# RESTORE_CM2 register map
Vendor: Texas Instruments
Peripheral module from a debugger description file (folder omap4460).
Registers are 32-bit, access per field, reset 0x0 unless marked. A register's access mark holds for its fields unless they carry their own. Offsets are as the file gives them; lines under a group give offsets from that group; [hi:lo] are bit positions; {n}, {i} and the like mark numbered series; 'fields as' and 'values as' point back to an identical list; <NAME> marks a mode.

## RESTORE_CM2
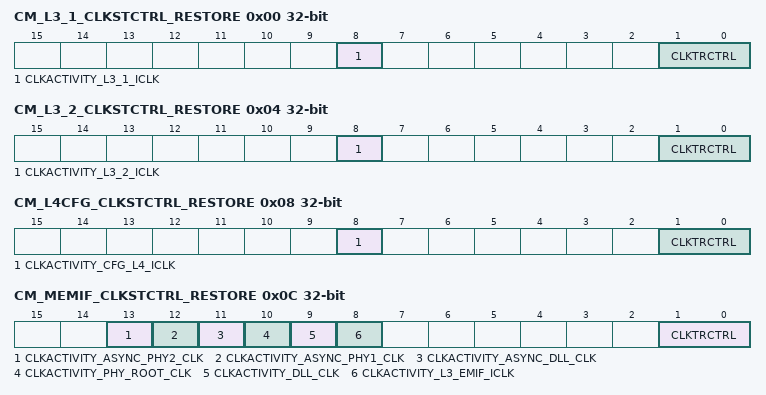
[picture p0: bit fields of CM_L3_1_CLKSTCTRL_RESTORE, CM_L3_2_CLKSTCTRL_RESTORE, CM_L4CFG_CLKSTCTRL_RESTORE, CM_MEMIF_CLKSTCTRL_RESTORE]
0x00 CM_L3_1_CLKSTCTRL_RESTORE — Second address map for register. Used only by automatic restore upon wakeup from device OFF mode.
  [8] CLKACTIVITY_L3_1_ICLK ro — This field indicates the state of the L3_1_GICLK clock in the domain. [warm reset insensitive]
    0=CLKACTIVITY_L3_1_ICLK_0_r (Corresponding clock is definitely gated); 1=CLKACTIVITY_L3_1_ICLK_1_r (Corresponding clock is running or gating/ungating transition is ongoing)
  [1:0] CLKTRCTRL rw — Controls the clock state transition of the L3_1 clock domain.
    0=NO_SLEEP: Sleep transition cannot be initiated. Wakeup transition may however occur.; 1=CLKTRCTRL_1_r (Reserved); 2=CLKTRCTRL_2_r (Reserved); 3=HW_AUTO: Automatic transition is enabled. Sleep and wakeup transition are based upon hardware conditions.
0x04 CM_L3_2_CLKSTCTRL_RESTORE — Second address map for register. Used only by automatic restore upon wakeup from device OFF mode.
  [8] CLKACTIVITY_L3_2_ICLK ro — This field indicates the state of the L3_2_GICLK clock in the domain. [warm reset insensitive]
    0=CLKACTIVITY_L3_2_ICLK_0_r (Corresponding clock is definitely gated); 1=CLKACTIVITY_L3_2_ICLK_1_r (Corresponding clock is running or gating/ungating transition is ongoing)
  [1:0] CLKTRCTRL rw — Controls the clock state transition of the L3_2 clock domain.
    values as CM_L3_1_CLKSTCTRL_RESTORE.CLKTRCTRL
0x08 CM_L4CFG_CLKSTCTRL_RESTORE — Second address map for register. Used only by automatic restore upon wakeup from device OFF mode.
  [8] CLKACTIVITY_CFG_L4_ICLK ro — This field indicates the state of the L4_CFG_GICLK clock in the domain. [warm reset insensitive]
    0=CLKACTIVITY_CFG_L4_ICLK_0_r (Corresponding clock is definitely gated); 1=CLKACTIVITY_CFG_L4_ICLK_1_r (Corresponding clock is running or gating/ungating transition is ongoing)
  [1:0] CLKTRCTRL rw — Controls the clock state transition of the L4CFG clock domain.
    values as CM_L3_1_CLKSTCTRL_RESTORE.CLKTRCTRL
0x0C CM_MEMIF_CLKSTCTRL_RESTORE — Second address map for register. Used only by automatic restore upon wakeup from device OFF mode.
  [13] CLKACTIVITY_ASYNC_PHY2_CLK ro — This field indicates the state of the ASYNC_PHY2_CLK clock in the domain. [warm reset insensitive]
    0=CLKACTIVITY_ASYNC_PHY2_CLK_0_r (Corresponding clock is definitely gated); 1=CLKACTIVITY_ASYNC_PHY2_CLK_1_r (Corresponding clock is running or gating/ungating transition is ongoing)
  [12] CLKACTIVITY_ASYNC_PHY1_CLK ro — This field indicates the state of the ASYNC_PHY1_CLK clock in the domain. [warm reset insensitive]
    0=CLKACTIVITY_ASYNC_PHY1_CLK_0_r (Corresponding clock is definitely gated); 1=CLKACTIVITY_ASYNC_PHY1_CLK_1_r (Corresponding clock is running or gating/ungating transition is ongoing)
  [11] CLKACTIVITY_ASYNC_DLL_CLK ro — This field indicates the state of the ASYNC_DLL_CLK clock in the domain. [warm reset insensitive]
    0=CLKACTIVITY_ASYNC_DLL_CLK_0_r (Corresponding clock is definitely gated); 1=CLKACTIVITY_ASYNC_DLL_CLK_1_r (Corresponding clock is running or gating/ungating transition is ongoing)
  [10] CLKACTIVITY_PHY_ROOT_CLK ro — This field indicates the state of the PHY_ROOT_CLK clock in the domain. [warm reset insensitive]
    0=CLKACTIVITY_PHY_ROOT_CLK_0_r (Corresponding clock is definitely gated); 1=CLKACTIVITY_PHY_ROOT_CLK_1_r (Corresponding clock is running or gating/ungating transition is ongoing)
  [9] CLKACTIVITY_DLL_CLK ro — This field indicates the state of the DLL_CLK clock in the domain. [warm reset insensitive]
    0=CLKACTIVITY_DLL_CLK_0_r (Corresponding clock is definitely gated); 1=CLKACTIVITY_DLL_CLK_1_r (Corresponding clock is running or gating/ungating transition is ongoing)
  [8] CLKACTIVITY_L3_EMIF_ICLK ro — This field indicates the state of the L3_EMIF_GICLK clock in the domain. [warm reset insensitive]
    0=CLKACTIVITY_L3_EMIF_ICLK_0_r (Corresponding clock is definitely gated); 1=CLKACTIVITY_L3_EMIF_ICLK_1_r (Corresponding clock is running or gating/ungating transition is ongoing)
  [1:0] CLKTRCTRL rw — Controls the clock state transition of the MEMIF clock domain.
    0=NO_SLEEP: Sleep transition cannot be initiated. Wakeup transition may however occur.; 1=CLKTRCTRL_1_r (Reserved); 2=SW_WKUP: Start a software forced wake-up transition on the domain; 3=HW_AUTO: Automatic transition is enabled. Sleep and wakeup transition are based upon hardware conditions.
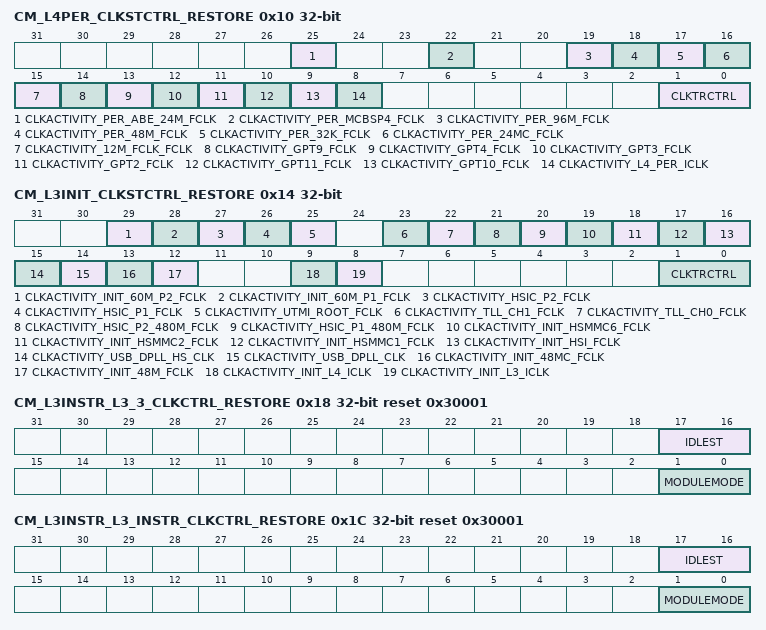
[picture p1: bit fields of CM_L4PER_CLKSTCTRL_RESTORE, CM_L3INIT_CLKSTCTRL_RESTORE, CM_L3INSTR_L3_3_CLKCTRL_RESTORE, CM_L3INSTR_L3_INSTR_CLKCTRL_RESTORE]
0x10 CM_L4PER_CLKSTCTRL_RESTORE — Second address map for register. Used only by automatic restore upon wakeup from device OFF mode.
  [25] CLKACTIVITY_PER_ABE_24M_FCLK ro — This field indicates the state of the PER_ABE_24M_FCLK clock in the domain. [warm reset insensitive]
    0=CLKACTIVITY_PER_ABE_24M_FCLK_0_r (Corresponding clock is definitely gated); 1=CLKACTIVITY_PER_ABE_24M_FCLK_1_r (Corresponding clock is running or gating/ungating transition is ongoing)
  [22] CLKACTIVITY_PER_MCBSP4_FCLK ro — This field indicates the state of the PER_MCBSP4_FCLK clock in the domain. [warm reset insensitive]
    0=CLKACTIVITY_PER_MCBSP4_FCLK_0_r (Corresponding clock is definitely gated); 1=CLKACTIVITY_PER_MCBSP4_FCLK_1_r (Corresponding clock is running or gating/ungating transition is ongoing)
  [19] CLKACTIVITY_PER_96M_FCLK ro — This field indicates the state of the PER_96M_FCLK clock in the domain. [warm reset insensitive]
    0=CLKACTIVITY_PER_96M_FCLK_0_r (Corresponding clock is definitely gated); 1=CLKACTIVITY_PER_96M_FCLK_1_r (Corresponding clock is running or gating/ungating transition is ongoing)
  [18] CLKACTIVITY_PER_48M_FCLK ro — This field indicates the state of the PER_48M_FCLK clock in the domain. [warm reset insensitive]
    0=CLKACTIVITY_PER_48M_FCLK_0_r (Corresponding clock is definitely gated); 1=CLKACTIVITY_PER_48M_FCLK_1_r (Corresponding clock is running or gating/ungating transition is ongoing)
  [17] CLKACTIVITY_PER_32K_FCLK ro — This field indicates the state of the PER_32K_FCLK clock in the domain. [warm reset insensitive]
    0=CLKACTIVITY_PER_32K_FCLK_0_r (Corresponding clock is definitely gated); 1=CLKACTIVITY_PER_32K_FCLK_1_r (Corresponding clock is running or gating/ungating transition is ongoing)
  [16] CLKACTIVITY_PER_24MC_FCLK ro — This field indicates the state of the PER_24MC_FCLK clock in the domain. [warm reset insensitive]
    0=CLKACTIVITY_PER_24MC_FCLK_0_r (Corresponding clock is definitely gated); 1=CLKACTIVITY_PER_24MC_FCLK_1_r (Corresponding clock is running or gating/ungating transition is ongoing)
  [15] CLKACTIVITY_12M_FCLK_FCLK ro — This field indicates the state of the FUNC_12M_FCLK clock in the domain. [warm reset insensitive]
    0=CLKACTIVITY_12M_FCLK_FCLK_0_r (Corresponding clock is definitely gated); 1=CLKACTIVITY_12M_FCLK_FCLK_1_r (Corresponding clock is running or gating/ungating transition is ongoing)
  [14] CLKACTIVITY_GPT9_FCLK ro — This field indicates the state of the DMT9_FCLK clock in the domain. [warm reset insensitive]
    0=CLKACTIVITY_GPT9_FCLK_0_r (Corresponding clock is definitely gated); 1=CLKACTIVITY_GPT9_FCLK_1_r (Corresponding clock is running or gating/ungating transition is ongoing)
  [13] CLKACTIVITY_GPT4_FCLK ro — This field indicates the state of the DMT4_FCLK clock in the domain. [warm reset insensitive]
    0=CLKACTIVITY_GPT4_FCLK_0_r (Corresponding clock is definitely gated); 1=CLKACTIVITY_GPT4_FCLK_1_r (Corresponding clock is running or gating/ungating transition is ongoing)
  [12] CLKACTIVITY_GPT3_FCLK ro — This field indicates the state of the DMT3_FCLK clock in the domain. [warm reset insensitive]
    0=CLKACTIVITY_GPT3_FCLK_0_r (Corresponding clock is definitely gated); 1=CLKACTIVITY_GPT3_FCLK_1_r (Corresponding clock is running or gating/ungating transition is ongoing)
  [11] CLKACTIVITY_GPT2_FCLK ro — This field indicates the state of the DMT2_FCLK clock in the domain. [warm reset insensitive]
    0=CLKACTIVITY_GPT2_FCLK_0_r (Corresponding clock is definitely gated); 1=CLKACTIVITY_GPT2_FCLK_1_r (Corresponding clock is running or gating/ungating transition is ongoing)
  [10] CLKACTIVITY_GPT11_FCLK ro — This field indicates the state of the DMT11_FCLK clock in the domain. [warm reset insensitive]
    0=CLKACTIVITY_GPT11_FCLK_0_r (Corresponding clock is definitely gated); 1=CLKACTIVITY_GPT11_FCLK_1_r (Corresponding clock is running or gating/ungating transition is ongoing)
  [9] CLKACTIVITY_GPT10_FCLK ro — This field indicates the state of the DMT10_FCLK clock in the domain. [warm reset insensitive]
    0=CLKACTIVITY_GPT10_FCLK_0_r (Corresponding clock is definitely gated); 1=CLKACTIVITY_GPT10_FCLK_1_r (Corresponding clock is running or gating/ungating transition is ongoing)
  [8] CLKACTIVITY_L4_PER_ICLK ro — This field indicates the state of the L4_PER_GICLK clock in the domain. [warm reset insensitive]
    0=CLKACTIVITY_L4_PER_ICLK_0_r (Corresponding clock is definitely gated); 1=CLKACTIVITY_L4_PER_ICLK_1_r (Corresponding clock is running or gating/ungating transition is ongoing)
  [1:0] CLKTRCTRL rw — Controls the clock state transition of the L4PER clock domain.
    0=NO_SLEEP: Sleep transition cannot be initiated. Wakeup transition may however occur.; 1=SW_SLEEP: Start a software forced sleep transition on the domain; 2=SW_WKUP: Start a software forced wake-up transition on the domain; 3=HW_AUTO: Automatic transition is enabled. Sleep and wakeup transition are based upon hardware conditions.
0x14 CM_L3INIT_CLKSTCTRL_RESTORE — Second address map for register. Used only by automatic restore upon wakeup from device OFF mode.
  [29] CLKACTIVITY_INIT_60M_P2_FCLK ro — This field indicates the state of the INIT_60M_P2_FCLK clock in the domain. [warm reset insensitive]
    0=CLKACTIVITY_INIT_60M_P2_FCLK_0_r (Corresponding clock is definitely gated); 1=CLKACTIVITY_INIT_60M_P2_FCLK_1_r (Corresponding clock is running or gating/ungating transition is ongoing)
  [28] CLKACTIVITY_INIT_60M_P1_FCLK ro — This field indicates the state of the INIT_60M_P1_FCLK clock in the domain. [warm reset insensitive]
    0=CLKACTIVITY_INIT_60M_P1_FCLK_0_r (Corresponding clock is definitely gated); 1=CLKACTIVITY_INIT_60M_P1_FCLK_1_r (Corresponding clock is running or gating/ungating transition is ongoing)
  [27] CLKACTIVITY_HSIC_P2_FCLK ro — This field indicates the state of the HSIC_P2_FCLK clock in the domain. [warm reset insensitive]
    0=CLKACTIVITY_HSIC_P2_FCLK_0_r (Corresponding clock is definitely gated); 1=CLKACTIVITY_HSIC_P2_FCLK_1_r (Corresponding clock is running or gating/ungating transition is ongoing)
  [26] CLKACTIVITY_HSIC_P1_FCLK ro — This field indicates the state of the HSIC_P1_FCLK clock in the domain. [warm reset insensitive]
    0=CLKACTIVITY_HSIC_P1_FCLK_0_r (Corresponding clock is definitely gated); 1=CLKACTIVITY_HSIC_P1_FCLK_1_r (Corresponding clock is running or gating/ungating transition is ongoing)
  [25] CLKACTIVITY_UTMI_ROOT_FCLK ro — This field indicates the state of the UTMI_ROOT_FCLK clock in the domain. [warm reset insensitive]
    0=CLKACTIVITY_UTMI_ROOT_FCLK_0_r (Corresponding clock is definitely gated); 1=CLKACTIVITY_UTMI_ROOT_FCLK_1_r (Corresponding clock is running or gating/ungating transition is ongoing)
  [23] CLKACTIVITY_TLL_CH1_FCLK ro — This field indicates the state of the TLL_CH1_FCLK clock in the domain. [warm reset insensitive]
    0=CLKACTIVITY_TLL_CH1_FCLK_0_r (Corresponding clock is definitely gated); 1=CLKACTIVITY_TLL_CH1_FCLK_1_r (Corresponding clock is running or gating/ungating transition is ongoing)
  [22] CLKACTIVITY_TLL_CH0_FCLK ro — This field indicates the state of the TLL_CH0_FCLK clock in the domain. [warm reset insensitive]
    0=CLKACTIVITY_TLL_CH0_FCLK_0_r (Corresponding clock is definitely gated); 1=CLKACTIVITY_TLL_CH0_FCLK_1_r (Corresponding clock is running or gating/ungating transition is ongoing)
  [21] CLKACTIVITY_HSIC_P2_480M_FCLK ro — This field indicates the state of the HSIC_P2_480M_FCLK clock in the domain. [warm reset insensitive]
    0=CLKACTIVITY_HSIC_P2_480M_FCLK_0_r (Corresponding clock is definitely gated); 1=CLKACTIVITY_HSIC_P2_480M_FCLK_1_r (Corresponding clock is running or gating/ungating transition is ongoing)
  [20] CLKACTIVITY_HSIC_P1_480M_FCLK ro — This field indicates the state of the HSIC_P1_480M_FCLK clock in the domain. [warm reset insensitive]
    0=CLKACTIVITY_HSIC_P1_480M_FCLK_0_r (Corresponding clock is definitely gated); 1=CLKACTIVITY_HSIC_P1_480M_FCLK_1_r (Corresponding clock is running or gating/ungating transition is ongoing)
  [19] CLKACTIVITY_INIT_HSMMC6_FCLK ro — This field indicates the state of the INIT_HSMMC6_FCLK clock in the domain. [warm reset insensitive]
    0=CLKACTIVITY_INIT_HSMMC6_FCLK_0_r (Corresponding clock is definitely gated); 1=CLKACTIVITY_INIT_HSMMC6_FCLK_1_r (Corresponding clock is running or gating/ungating transition is ongoing)
  [18] CLKACTIVITY_INIT_HSMMC2_FCLK ro — This field indicates the state of the INIT_HSMMC2_FCLK clock in the domain. [warm reset insensitive]
    0=CLKACTIVITY_INIT_HSMMC2_FCLK_0_r (Corresponding clock is definitely gated); 1=CLKACTIVITY_INIT_HSMMC2_FCLK_1_r (Corresponding clock is running or gating/ungating transition is ongoing)
  [17] CLKACTIVITY_INIT_HSMMC1_FCLK ro — This field indicates the state of the INIT_HSMMC1_FCLK clock in the domain. [warm reset insensitive]
    0=CLKACTIVITY_INIT_HSMMC1_FCLK_0_r (Corresponding clock is definitely gated); 1=CLKACTIVITY_INIT_HSMMC1_FCLK_1_r (Corresponding clock is running or gating/ungating transition is ongoing)
  [16] CLKACTIVITY_INIT_HSI_FCLK ro — This field indicates the state of the INIT_HSI_FCLK clock in the domain. [warm reset insensitive]
    0=CLKACTIVITY_INIT_HSI_FCLK_0_r (Corresponding clock is definitely gated); 1=CLKACTIVITY_INIT_HSI_FCLK_1_r (Corresponding clock is running or gating/ungating transition is ongoing)
  [15] CLKACTIVITY_USB_DPLL_HS_CLK ro — This field indicates the state of the USB_DPLL_HS_CLK clock in the domain. [warm reset insensitive]
    0=CLKACTIVITY_USB_DPLL_HS_CLK_0_r (Corresponding clock is definitely gated); 1=CLKACTIVITY_USB_DPLL_HS_CLK_1_r (Corresponding clock is running or gating/ungating transition is ongoing)
  [14] CLKACTIVITY_USB_DPLL_CLK ro — This field indicates the state of the USB_DPLL_CLK clock in the domain. [warm reset insensitive]
    0=CLKACTIVITY_USB_DPLL_CLK_0_r (Corresponding clock is definitely gated); 1=CLKACTIVITY_USB_DPLL_CLK_1_r (Corresponding clock is running or gating/ungating transition is ongoing)
  [13] CLKACTIVITY_INIT_48MC_FCLK ro — This field indicates the state of the INIT_48MC_FCLK clock in the domain. [warm reset insensitive]
    0=CLKACTIVITY_INIT_48MC_FCLK_0_r (Corresponding clock is definitely gated); 1=CLKACTIVITY_INIT_48MC_FCLK_1_r (Corresponding clock is running or gating/ungating transition is ongoing)
  [12] CLKACTIVITY_INIT_48M_FCLK ro — This field indicates the state of the INIT_48M_FCLK clock in the domain. [warm reset insensitive]
    0=CLKACTIVITY_INIT_48M_FCLK_0_r (Corresponding clock is definitely gated); 1=CLKACTIVITY_INIT_48M_FCLK_1_r (Corresponding clock is running or gating/ungating transition is ongoing)
  [9] CLKACTIVITY_INIT_L4_ICLK ro — This field indicates the state of the L4_INIT_GICLK clock in the domain. [warm reset insensitive]
    0=CLKACTIVITY_INIT_L4_ICLK_0_r (Corresponding clock is definitely gated); 1=CLKACTIVITY_INIT_L4_ICLK_1_r (Corresponding clock is running or gating/ungating transition is ongoing)
  [8] CLKACTIVITY_INIT_L3_ICLK ro — This field indicates the state of the L3_INIT_GICLK clock in the domain. [warm reset insensitive]
    0=CLKACTIVITY_INIT_L3_ICLK_0_r (Corresponding clock is definitely gated); 1=CLKACTIVITY_INIT_L3_ICLK_1_r (Corresponding clock is running or gating/ungating transition is ongoing)
  [1:0] CLKTRCTRL rw — Controls the clock state transition of the L3INIT clock domain.
    values as CM_L4PER_CLKSTCTRL_RESTORE.CLKTRCTRL
0x18 CM_L3INSTR_L3_3_CLKCTRL_RESTORE reset 0x30001 — Second address map for register. Used only by automatic restore upon wakeup from device OFF mode.
  [17:16] IDLEST ro — Module idle status. [warm reset insensitive]
    0=IDLEST_0_r (Module is fully functional, including INTRCONN); 1=IDLEST_1_r (Module is performing transition: wakeup, or sleep, or sleep abortion); 2=IDLEST_2_r (Module is in idle mode (only INTRCONN part). It is functional if using separate functional clock); 3=IDLEST_3_r (Module is disabled and cannot be accessed)
  [1:0] MODULEMODE rw — Control the way mandatory clocks are managed.
    0=Module is disable by software. Any INTRCONN access to module results in an error, except if resulting from a module wakeup (asynchronous wakeup).; 1=Module is managed automatically by hardware according to clock domain transition. A clock domain sleep transition put module into idle. A wakeup domain transition put it back into function. If CLKTRCTRL=3, any INTRCONN access to module is always granted. Module clocks may be gated according to the clock domain state.; 2=MODULEMODE_2_r (Reserved); 3=MODULEMODE_3_r (Reserved)
0x1C CM_L3INSTR_L3_INSTR_CLKCTRL_RESTORE reset 0x30001 — Second address map for register. Used only by automatic restore upon wakeup from device OFF mode.
  fields as CM_L3INSTR_L3_3_CLKCTRL_RESTORE
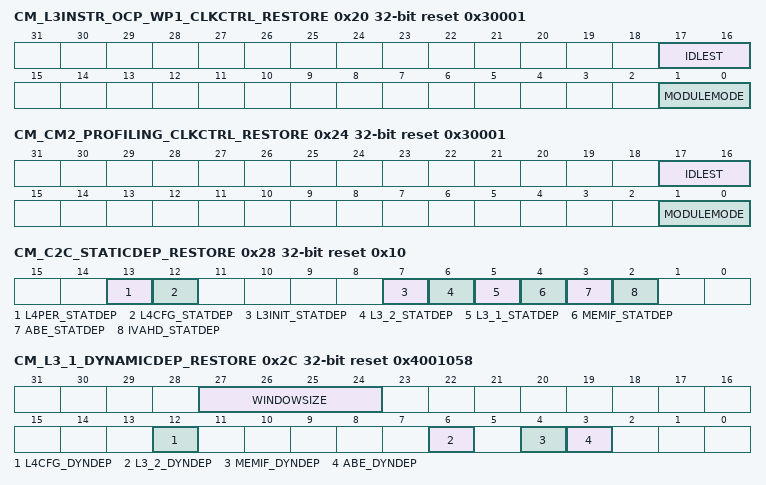
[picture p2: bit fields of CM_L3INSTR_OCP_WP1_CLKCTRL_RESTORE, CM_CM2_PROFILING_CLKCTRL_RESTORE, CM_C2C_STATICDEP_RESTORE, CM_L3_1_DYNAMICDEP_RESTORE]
0x20 CM_L3INSTR_OCP_WP1_CLKCTRL_RESTORE reset 0x30001 — Second address map for register. Used only by automatic restore upon wakeup from device OFF mode.
  [17:16] IDLEST ro — Module idle status. [warm reset insensitive]
    3=IDLEST_3_r (Module is disabled and cannot be accessed); 2=IDLEST_2_r (Module is in idle mode (only Interconnect part). It is functional if using separate functional clock); 1=IDLEST_1_r (Module is performing transition: wakeup, or sleep, or sleep abortion); 0=IDLEST_0_r (Module is fully functional, including Interconnect)
  [1:0] MODULEMODE rw — Control the way mandatory clocks are managed.
    0=Module is disable by software. Any Interconnect access to module results in an error, except if resulting from a module wakeup (asynchronous wakeup).; 1=Module is managed automatically by hardware according to clock domain transition. A clock domain sleep transition put module into idle. A wakeup domain transition put it back into function. If CLKTRCTRL=3, any Interconnect access to module is always granted. Module clocks may be gated according to the clock domain state.; 2=MODULEMODE_2_r (Reserved); 3=MODULEMODE_3_r (Reserved)
0x24 CM_CM2_PROFILING_CLKCTRL_RESTORE reset 0x30001 — Second address map for register. Used only by automatic restore upon wakeup from device OFF mode. [warm reset insensitive]
  [17:16] IDLEST ro — Module idle status
    3=IDLEST_3_r (Module is disabled); 2=IDLEST_2_r (Module is in Idle); 1=IDLEST_1_r (Module is performing transition: wakeup, or sleep, or sleep abortion); 0=IDLEST_0_r (Module is fully functional)
  [1:0] MODULEMODE rw — Control the way mandatory clocks are managed.
    0=Module is disabled by software. OCP configuration port is not accessible.; 1=Module is managed automatically by hardware along with L3INSTR domain; 2=MODULEMODE_2_r (Reserved); 3=MODULEMODE_3_r (Reserved)
0x28 CM_C2C_STATICDEP_RESTORE reset 0x10 — Second address map for register. Used only by automatic restore upon wakeup from device OFF mode.
  [all] fields
    0=Dependency is disabled; 1=Dependency is enabled
  [13] L4PER_STATDEP rw — Static dependency towards L4PER clock domain
  [12] L4CFG_STATDEP rw — Static dependency towards L4CFG clock domain
  [7] L3INIT_STATDEP rw — Static dependency towards L3INIT clock domain
  [6] L3_2_STATDEP rw — Static dependency towards L3_2 clock domain
  [5] L3_1_STATDEP rw — Static dependency towards L3_1 clock domain
  [4] MEMIF_STATDEP rw — Static dependency towards MEMIF clock domain
  [3] ABE_STATDEP rw — Static dependency towards ABE clock domain
  [2] IVAHD_STATDEP rw — Static dependency towards IVAHD clock domain
0x2C CM_L3_1_DYNAMICDEP_RESTORE access not given reset 0x4001058 — Second address map for register. Used only by automatic restore upon wakeup from device OFF mode.
  [27:24] WINDOWSIZE rw — Size of sliding window used to monitor OCP interface activity for determination of auto-sleep feature. Time unit defined byCM_DYN_DEP_PRESCAL register.
  [12] L4CFG_DYNDEP — Dynamic dependency towards L4CFG clock domain (access R Rreturns1s)
    1=L4CFG_DYNDEP_1_r (Dependency is enabled)
  [6] L3_2_DYNDEP — Dynamic dependency towards L3_2 clock domain (access R Rreturns1s)
    1=L3_2_DYNDEP_1_r (Dependency is enabled)
  [4] MEMIF_DYNDEP — Dynamic dependency towards MEMIF clock domain (access R Rreturns1s)
    1=MEMIF_DYNDEP_1_r (Dependency is enabled)
  [3] ABE_DYNDEP — Dynamic dependency towards ABE clock domain (access R Rreturns1s)
    1=ABE_DYNDEP_1_r (Dependency is enabled)
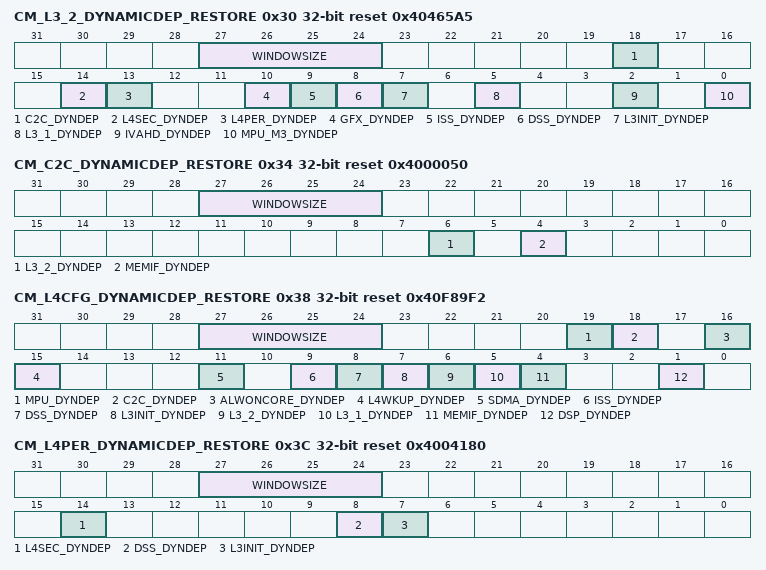
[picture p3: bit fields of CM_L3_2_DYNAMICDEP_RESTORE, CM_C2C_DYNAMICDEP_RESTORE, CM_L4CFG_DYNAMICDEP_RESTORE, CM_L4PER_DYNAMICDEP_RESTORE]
0x30 CM_L3_2_DYNAMICDEP_RESTORE access not given reset 0x40465A5 — Second address map for register. Used only by automatic restore upon wakeup from device OFF mode.
  [27:24] WINDOWSIZE rw — Size of sliding window used to monitor OCP interface activity for determination of auto-sleep feature. Time unit defined byCM_DYN_DEP_PRESCAL register.
  [18] C2C_DYNDEP — Dynamic dependency towards D2D clock domain (access R Rreturns1s)
    1=C2C_DYNDEP_1_r (Dependency is enabled)
  [14] L4SEC_DYNDEP ro — Dynamic dependency towards L4SEC clock domain
    1=L4SEC_DYNDEP_1_r (Dependency is enabled)
  [13] L4PER_DYNDEP — Dynamic dependency towards L4PER clock domain (access R Rreturns1s)
    1=L4PER_DYNDEP_1_r (Dependency is enabled)
  [10] GFX_DYNDEP — Dynamic dependency towards GFX clock domain (access R Rreturns1s)
    1=GFX_DYNDEP_1_r (Dependency is enabled)
  [9] ISS_DYNDEP ro — Dynamic dependency towards ISS clock domain
    0=ISS_DYNDEP_0_r (Dependency is disabled)
  [8] DSS_DYNDEP — Dynamic dependency towards DSS clock domain (access R Rreturns1s)
    1=DSS_DYNDEP_1_r (Dependency is enabled)
  [7] L3INIT_DYNDEP — Dynamic dependency towards L3INIT clock domain (access R Rreturns1s)
    1=L3INIT_DYNDEP_1_r (Dependency is enabled)
  [5] L3_1_DYNDEP — Dynamic dependency towards L3_1 clock domain (access R Rreturns1s)
    1=L3_1_DYNDEP_1_r (Dependency is enabled)
  [2] IVAHD_DYNDEP — Dynamic dependency towards IVAHD clock domain (access R Rreturns1s)
    1=IVAHD_DYNDEP_1_r (Dependency is enabled)
  [0] MPU_M3_DYNDEP — Dynamic dependency towards CORTEXM3 clock domain (access R Rreturns1s)
    1=MPU_M3_DYNDEP_1_r (Dependency is enabled)
0x34 CM_C2C_DYNAMICDEP_RESTORE access not given reset 0x4000050 — Second address map for register. Used only by automatic restore upon wakeup from device OFF mode.
  [27:24] WINDOWSIZE rw — Size of sliding window used to monitor OCP interface activity for determination of auto-sleep feature. Time unit defined byCM_DYN_DEP_PRESCAL register.
  [6] L3_2_DYNDEP — Dynamic dependency towards L3_2 clock domain (access R Rreturns1s)
    1=L3_2_DYNDEP_1_r (Dependency is enabled)
  [4] MEMIF_DYNDEP — Dynamic dependency towards MEMIF clock domain (access R Rreturns1s)
    1=MEMIF_DYNDEP_1_r (Dependency is enabled)
0x38 CM_L4CFG_DYNAMICDEP_RESTORE access not given reset 0x40F89F2 — Second address map for register. Used only by automatic restore upon wakeup from device OFF mode.
  [27:24] WINDOWSIZE rw — Size of sliding window used to monitor OCP interface activity for determination of auto-sleep feature. Time unit defined byCM_DYN_DEP_PRESCAL register.
  [19] MPU_DYNDEP — Dynamic dependency towards MPU clock domain (access R Rreturns1s)
    1=MPU_DYNDEP_1_r (Dependency is enabled)
  [18] C2C_DYNDEP — Dynamic dependency towards D2D clock domain (access R Rreturns1s)
    1=C2C_DYNDEP_1_r (Dependency is enabled)
  [16] ALWONCORE_DYNDEP — Dynamic dependency towards ALWONCORE clock domain (access R Rreturns1s)
    1=ALWONCORE_DYNDEP_1_r (Dependency is enabled)
  [15] L4WKUP_DYNDEP — Dynamic dependency towards L4WKUP clock domain (access R Rreturns1s)
    1=L4WKUP_DYNDEP_1_r (Dependency is enabled)
  [11] SDMA_DYNDEP — Dynamic dependency towards SDMA clock domain (access R Rreturns1s)
    1=SDMA_DYNDEP_1_r (Dependency is enabled)
  [9] ISS_DYNDEP ro — Dynamic dependency towards ISS clock domain
    0=ISS_DYNDEP_0_r (Dependency is disabled)
  [8] DSS_DYNDEP — Dynamic dependency towards DSS clock domain (access R Rreturns1s)
    1=DSS_DYNDEP_1_r (Dependency is enabled)
  [7] L3INIT_DYNDEP — Dynamic dependency towards L3INIT clock domain (access R Rreturns1s)
    1=L3INIT_DYNDEP_1_r (Dependency is enabled)
  [6] L3_2_DYNDEP — Dynamic dependency towards L3_2 clock domain (access R Rreturns1s)
    1=L3_2_DYNDEP_1_r (Dependency is enabled)
  [5] L3_1_DYNDEP — Dynamic dependency towards L3_1 clock domain (access R Rreturns1s)
    1=L3_1_DYNDEP_1_r (Dependency is enabled)
  [4] MEMIF_DYNDEP — Dynamic dependency towards MEMIF clock domain (access R Rreturns1s)
    1=MEMIF_DYNDEP_1_r (Dependency is enabled)
  [1] DSP_DYNDEP — Dynamic dependency towards DSP clock domain (access R Rreturns1s)
    1=DSP_DYNDEP_1_r (Dependency is enabled)
0x3C CM_L4PER_DYNAMICDEP_RESTORE access not given reset 0x4004180 — Second address map for register. Used only by automatic restore upon wakeup from device OFF mode.
  [27:24] WINDOWSIZE rw — Size of sliding window used to monitor OCP interface activity for determination of auto-sleep feature. Time unit defined byCM_DYN_DEP_PRESCAL register.
  [14] L4SEC_DYNDEP ro — Dynamic dependency towards L4SEC clock domain
    1=L4SEC_DYNDEP_1_r (Dependency is enabled)
  [8] DSS_DYNDEP — Dynamic dependency towards DSS clock domain (access R Rreturns1s)
    1=DSS_DYNDEP_1_r (Dependency is enabled)
  [7] L3INIT_DYNDEP — Dynamic dependency towards L3INIT clock domain (access R Rreturns1s)
    1=L3INIT_DYNDEP_1_r (Dependency is enabled)
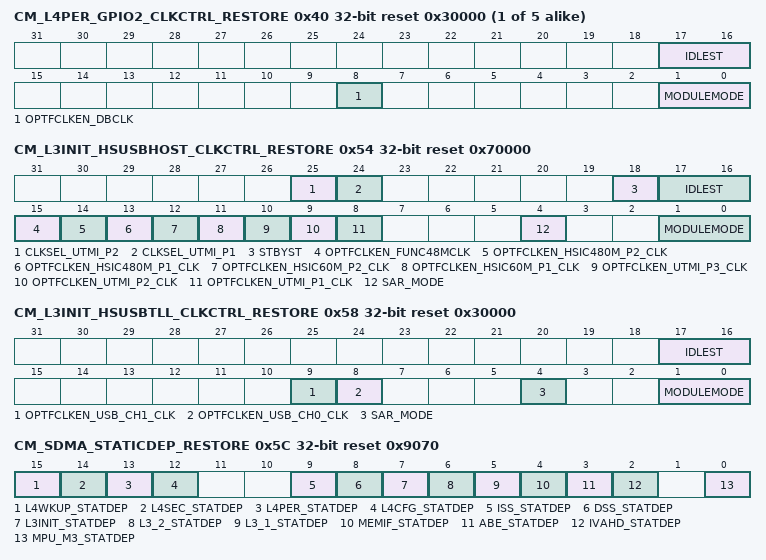
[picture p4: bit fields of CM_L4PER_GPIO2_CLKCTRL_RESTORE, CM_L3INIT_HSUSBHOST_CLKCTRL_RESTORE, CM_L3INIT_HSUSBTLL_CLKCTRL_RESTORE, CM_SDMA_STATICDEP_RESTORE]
{0x38+4i} CM_L4PER_GPIO{i}_CLKCTRL_RESTORE reset 0x30000 (i=2..6) — Second address map for register. Used only by automatic restore upon wakeup from device OFF mode.
  [17:16] IDLEST ro — Module idle status. [warm reset insensitive]
    values as CM_L3INSTR_L3_3_CLKCTRL_RESTORE.IDLEST
  [8] OPTFCLKEN_DBCLK rw — Optional functional clock control.
    0=Optional functional clock is disabled; 1=Optional functional clock is enabled
  [1:0] MODULEMODE rw — Control the way mandatory clocks are managed.
    values as CM_L3INSTR_L3_3_CLKCTRL_RESTORE.MODULEMODE
0x54 CM_L3INIT_HSUSBHOST_CLKCTRL_RESTORE reset 0x70000 — Second address map for register CM_L3INIT_USB_HOST_CLKCTRL. Used only by automatic restore upon wakeup from device OFF mode.
  [25] CLKSEL_UTMI_P2 rw — Selects the source of the functional clock for UTMI Port2 on USB Host
    0=The functional clock is provided by the internal clock source; 1=The functional clock is provided by an external PHY through an I/O pad
  [24] CLKSEL_UTMI_P1 rw — Selects the source of the functional clock for UTMI Por1 on USB Host
    values as CLKSEL_UTMI_P2
  [18] STBYST ro — Module standby status. [warm reset insensitive]
    0=STBYST_0_r (Module is functional (not in standby)); 1=STBYST_1_r (Module is in standby)
  [17:16] IDLEST ro — Module idle status. [warm reset insensitive]
    values as CM_L3INSTR_L3_3_CLKCTRL_RESTORE.IDLEST
  [15] OPTFCLKEN_FUNC48MCLK rw — USB-HOST optional clock control: FUNC48MCLK
    values as CM_L4PER_GPIO2_CLKCTRL_RESTORE.OPTFCLKEN_DBCLK
  [14] OPTFCLKEN_HSIC480M_P2_CLK rw — USB-HOST optional clock control: HSIC480M_P2_CLK
    values as CM_L4PER_GPIO2_CLKCTRL_RESTORE.OPTFCLKEN_DBCLK
  [13] OPTFCLKEN_HSIC480M_P1_CLK rw — USB-HOST optional clock control: HSIC480M_P1_CLK
    values as CM_L4PER_GPIO2_CLKCTRL_RESTORE.OPTFCLKEN_DBCLK
  [12] OPTFCLKEN_HSIC60M_P2_CLK rw — USB-HOST optional clock control: HSIC60M_P2_CLK
    values as CM_L4PER_GPIO2_CLKCTRL_RESTORE.OPTFCLKEN_DBCLK
  [11] OPTFCLKEN_HSIC60M_P1_CLK rw — USB-HOST optional clock control: HSIC60M_P1_CLK
    values as CM_L4PER_GPIO2_CLKCTRL_RESTORE.OPTFCLKEN_DBCLK
  [10] OPTFCLKEN_UTMI_P3_CLK rw — USB-HOST optional clock control: UTMI_P3_CLK
    values as CM_L4PER_GPIO2_CLKCTRL_RESTORE.OPTFCLKEN_DBCLK
  [9] OPTFCLKEN_UTMI_P2_CLK rw — USB-HOST optional clock control: UTMI_P2_CLK when CLKSEL_UTMI_P2 is 0
    values as CM_L4PER_GPIO2_CLKCTRL_RESTORE.OPTFCLKEN_DBCLK
  [8] OPTFCLKEN_UTMI_P1_CLK rw — USB-HOST optional clock control: UTMI_P1_CLK when CLKSEL_UTMI_P1 is 0
    values as CM_L4PER_GPIO2_CLKCTRL_RESTORE.OPTFCLKEN_DBCLK
  [4] SAR_MODE rw — SAR mode control for the module. Shall not be modify except if module is disabled.
    0=SAR mode is disabled; 1=SAR mode is enabled
  [1:0] MODULEMODE rw — Control the way mandatory clocks are managed.
    0=Module is disable by software. Any INTRCONN access to module results in an error, except if resulting from a module wakeup (asynchronous wakeup).; 1=MODULEMODE_1_r (Reserved); 2=Module is explicitly enabled. Interface clock (if not used for functions) may be gated according to the clock domain state. Functional clocks are guarantied to stay present. As long as in this configuration, power domain sleep transition cannot happen.; 3=MODULEMODE_3_r (Reserved)
0x58 CM_L3INIT_HSUSBTLL_CLKCTRL_RESTORE reset 0x30000 — Second address map for register. Used only by automatic restore upon wakeup from device OFF mode.
  [17:16] IDLEST ro — Module idle status. [warm reset insensitive]
    values as CM_L3INSTR_L3_3_CLKCTRL_RESTORE.IDLEST
  [9] OPTFCLKEN_USB_CH1_CLK rw — USB-HOST optional clock control: USB_CH1_CLK
    values as CM_L4PER_GPIO2_CLKCTRL_RESTORE.OPTFCLKEN_DBCLK
  [8] OPTFCLKEN_USB_CH0_CLK rw — USB-HOST optional clock control: USB_CH0_CLK
    values as CM_L4PER_GPIO2_CLKCTRL_RESTORE.OPTFCLKEN_DBCLK
  [4] SAR_MODE rw — SAR mode control for the module. Shall not be modify except if module is disabled.
    0=SAR mode is disabled; 1=SAR mode is enabled
  [1:0] MODULEMODE rw — Control the way mandatory clocks are managed.
    values as CM_L3INSTR_L3_3_CLKCTRL_RESTORE.MODULEMODE
0x5C CM_SDMA_STATICDEP_RESTORE access not given reset 0x9070 — Second address map for register. Used only by automatic restore upon wakeup from device OFF mode.
  [15] L4WKUP_STATDEP rw — Static dependency towards L4WKUP clock domain
    0=Dependency is disabled; 1=Dependency is enabled
  [14] L4SEC_STATDEP rw — Static dependency towards L4SEC clock domain
  [13] L4PER_STATDEP rw — Static dependency towards L4PER clock domain
    0=Dependency is disabled; 1=Dependency is enabled
  [12] L4CFG_STATDEP rw — Static dependency towards L4CFG clock domain
    0=Dependency is disabled; 1=Dependency is enabled
  [9] ISS_STATDEP ro — Static dependency towards ISS clock domain
    0=ISS_STATDEP_0_r (Dependency is disabled)
  [8] DSS_STATDEP rw — Static dependency towards DSS clock domain
    0=Dependency is disabled; 1=Dependency is enabled
  [7] L3INIT_STATDEP rw — Static dependency towards L3INIT clock domain
    0=Dependency is disabled; 1=Dependency is enabled
  [6] L3_2_STATDEP — Static dependency towards L3_2 clock domain (access R Rreturns1s)
    1=L3_2_STATDEP_1_r (Dependency is enabled)
  [5] L3_1_STATDEP rw — Static dependency towards L3_1 clock domain
    0=Dependency is disabled; 1=Dependency is enabled
  [4] MEMIF_STATDEP rw — Static dependency towards MEMIF clock domain
    0=Dependency is disabled; 1=Dependency is enabled
  [3] ABE_STATDEP rw — Static dependency towards ABE clock domain
    0=Dependency is disabled; 1=Dependency is enabled
  [2] IVAHD_STATDEP rw — Static dependency towards IVAHD clock domain
    0=Dependency is disabled; 1=Dependency is enabled
  [0] MPU_M3_STATDEP rw — Static dependency towards MPU_A3 clock domain
    0=Dependency is disabled; 1=Dependency is enabled
